VERSION ""

NS_ :

BS_:

BU_: VCU RSM

BO_ 3221225472 VECTOR__INDEPENDENT_SIG_MSG: 0 Vector__XXX
 SG_ NewSignal_0003 : 16|8@1+ (1,0) [0|0] "" Vector__XXX
 SG_ NewSignal_0012 : 0|8@1+ (1,0) [0|0] "" Vector__XXX
 SG_ NewSignal_0013 : 0|8@1+ (1,0) [0|0] "" Vector__XXX

BO_ 2436890623 PWM_SW_1_2: 8 VCU
 SG_ PWM_SW_1 : 0|16@1+ (0.01,0) [0|100] "%" Vector__XXX
 SG_ PWM_SW_2 : 16|16@1+ (0.01,0) [0|100] "%" Vector__XXX

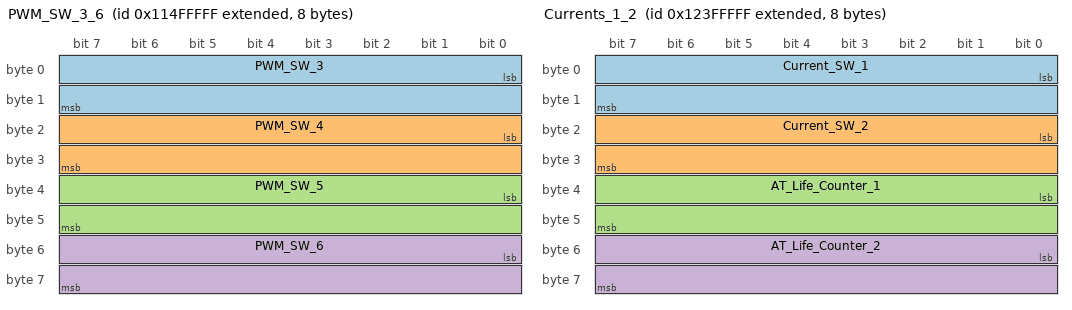
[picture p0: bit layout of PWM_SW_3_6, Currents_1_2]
BO_ 2437939199 PWM_SW_3_6: 8 VCU
 SG_ PWM_SW_3 : 0|16@1+ (0.01,0) [0|100] "%" Vector__XXX
 SG_ PWM_SW_4 : 16|16@1+ (0.01,0) [0|100] "%" Vector__XXX
 SG_ PWM_SW_5 : 32|16@1+ (0.01,0) [0|100] "%" Vector__XXX
 SG_ PWM_SW_6 : 48|16@1+ (0.01,0) [0|100] "%" Vector__XXX

BO_ 2453667839 Currents_1_2: 8 RSM
 SG_ Current_SW_1 : 0|16@1+ (0.00125,0) [0|10.3226] "A" Vector__XXX
 SG_ Current_SW_2 : 16|16@1+ (0.00125,0) [0|10.3226] "A" Vector__XXX
 SG_ AT_Life_Counter_1 : 32|16@1+ (1,0) [0|0] "" Vector__XXX
 SG_ AT_Life_Counter_2 : 48|16@1+ (1,0) [0|0] "" Vector__XXX

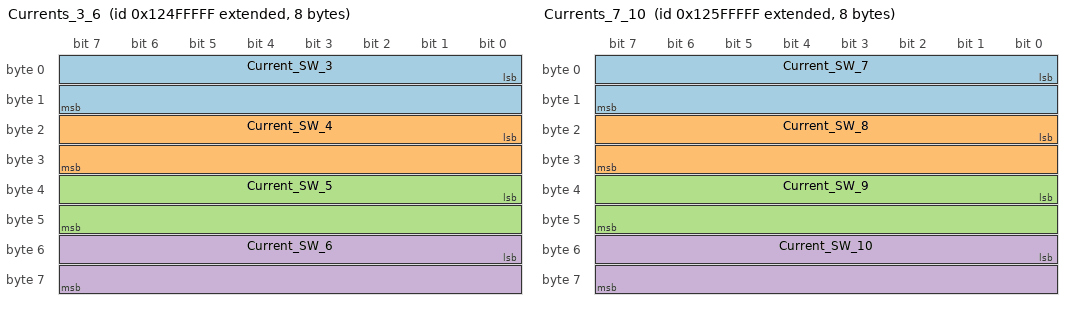
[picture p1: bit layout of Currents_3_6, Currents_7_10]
BO_ 2454716415 Currents_3_6: 8 RSM
 SG_ Current_SW_3 : 0|16@1+ (0.00125,0) [0|10.3226] "A" Vector__XXX
 SG_ Current_SW_4 : 16|16@1+ (0.00125,0) [0|10.3226] "A" Vector__XXX
 SG_ Current_SW_5 : 32|16@1+ (0.00125,0) [0|10.3226] "A" Vector__XXX
 SG_ Current_SW_6 : 48|16@1+ (0.00125,0) [0|10.3226] "A" Vector__XXX

BO_ 2455764991 Currents_7_10: 8 RSM
 SG_ Current_SW_7 : 0|16@1+ (0.00125,0) [0|10.3226] "A" Vector__XXX
 SG_ Current_SW_8 : 16|16@1+ (0.00125,0) [0|10.3226] "A" Vector__XXX
 SG_ Current_SW_9 : 32|16@1+ (0.00125,0) [0|10.3226] "A" Vector__XXX
 SG_ Current_SW_10 : 48|16@1+ (0.00125,0) [0|10.3226] "A" Vector__XXX

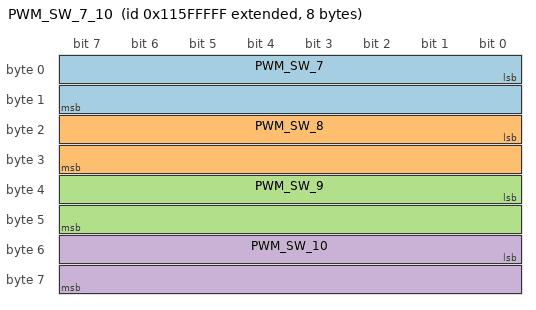
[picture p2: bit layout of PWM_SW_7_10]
BO_ 2438987775 PWM_SW_7_10: 8 VCU
 SG_ PWM_SW_7 : 0|16@1+ (0.01,0) [0|100] "%" Vector__XXX
 SG_ PWM_SW_8 : 16|16@1+ (0.01,0) [0|100] "%" Vector__XXX
 SG_ PWM_SW_9 : 32|16@1+ (0.01,0) [0|100] "%" Vector__XXX
 SG_ PWM_SW_10 : 48|16@1+ (0.01,0) [0|100] "%" Vector__XXX
